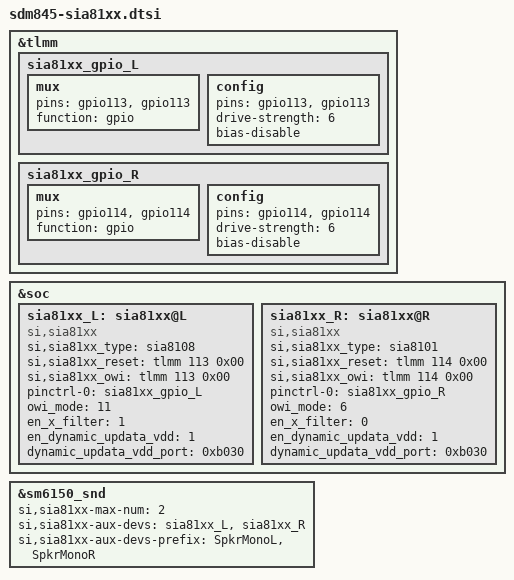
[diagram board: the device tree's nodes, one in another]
/* Copyright (c) 2018, The Linux Foundation. All rights reserved.
 *
 * This program is free software; you can redistribute it and/or modify
 * it under the terms of the GNU General Public License version 2 and
 * only version 2 as published by the Free Software Foundation.
 *
 * This program is distributed in the hope that it will be useful,
 * but WITHOUT ANY WARRANTY; without even the implied warranty of
 * MERCHANTABILITY or FITNESS FOR A PARTICULAR PURPOSE.  See the
 * GNU General Public License for more details.
 */

&tlmm {
	sia81xx_gpio_L: sia81xx_gpio_L {
		mux {
			pins = "gpio113", "gpio113";
			function = "gpio";
		};

		config {
			pins = "gpio113", "gpio113";
			drive-strength = <6>;
			bias-disable;
		};
	};

	sia81xx_gpio_R: sia81xx_gpio_R {
		mux {
			pins = "gpio114", "gpio114";
			function = "gpio";
		};

		config {
			pins = "gpio114", "gpio114";
			drive-strength = <6>;
			bias-disable;
		};
	};

};

&soc {
	sia81xx_L: sia81xx@L {
			compatible = "si,sia81xx";
			si,sia81xx_type = "sia8108";
			si,sia81xx_reset = <&tlmm 113 0x00>;
			si,sia81xx_owi = <&tlmm 113 0x00>;
			pinctrl-names = "sia81xx_gpio";
			pinctrl-0 = <&sia81xx_gpio_L>;

			owi_mode = <11>;
			en_x_filter = <1>;
			en_dynamic_updata_vdd = <1>;
			dynamic_updata_vdd_port = <0xb030>;
	};

	sia81xx_R: sia81xx@R {
			compatible = "si,sia81xx";
			si,sia81xx_type = "sia8101";
			si,sia81xx_reset = <&tlmm 114 0x00>;
			si,sia81xx_owi = <&tlmm 114 0x00>;
			pinctrl-names = "sia81xx_gpio";
			pinctrl-0 = <&sia81xx_gpio_R>;

			owi_mode = <6>;
			en_x_filter = <0>;
			en_dynamic_updata_vdd = <1>;
			dynamic_updata_vdd_port = <0xb030>;
	};

};

&sm6150_snd {
	si,sia81xx-max-num = <2>;
	si,sia81xx-aux-devs = <&sia81xx_L> , <&sia81xx_R>;
	si,sia81xx-aux-devs-prefix = "SpkrMonoL","SpkrMonoR";
};

/*
&qupv3_se11_i2c {
	status = "ok";

	sia81xx_i2c_L: sia81xx_i2c@L {
		compatible = "si,sia81xx-i2c";
		reg = <0x28>;
		si,sia81xx-dev = <&sia81xx_L>;
	};

	sia81xx_i2c_R: sia81xx_i2c@R {
		compatible = "si,sia81xx-i2c";
		reg = <0x2b>;
		si,sia81xx-dev = <&sia81xx_R>;
	};
};
*/
/*
&i2c_6 {
	sia8108_i2c_28: sia8108_i2c@28 {
		compatible = "si,sia8108-i2c";
		reg = <0x28>;
		si,sia8108-dev = <&sia8108_28>;
	};

	sia8108_i2c_2b: sia8108_i2c@2b {
		compatible = "si,sia8108-i2c";
		reg = <0x2b>;
		si,sia8108-dev = <&sia8108_2b>;
	};
};
*/
























/*
&soc {
	sia8108_28: sia8108@28 {
			compatible = "si,sia8108";
			si,sia8108-dev-name = "sia8108-28";
			si,sia8108_reset = <&tlmm 25 0x00>;
			si,sia8108_owi = <&tlmm 25 0x00>;
			pinctrl-names = "sia8108_gpio";
			pinctrl-0 = <&sia8108_gpio_L>;
	};

	sia8108_2b: sia8108@2b {
			compatible = "si,sia8108";
			si,sia8108-dev-name = "sia8108-2b";
			si,sia8108_reset = <&tlmm 26 0x00>;
			si,sia8108_owi = <&tlmm 26 0x00>;
			pinctrl-names = "sia8108_gpio";
			pinctrl-0 = <&sia8108_gpio_R>;
	};
};

&i2c_6 {
	sia8108_i2c_28: sia8108_i2c@28 {
		compatible = "si,sia8108-i2c";
		reg = <0x28>;
		si,sia8108-dev = <&sia8108_28>;
		si,sia8108-dev-name = "sia8108-28";
	};

	sia8108_i2c_2b: sia8108_i2c@2b {
		compatible = "si,sia8108-i2c";
		reg = <0x2b>;
		si,sia8108-dev = <&sia8108_2b>;
		si,sia8108-dev-name = "sia8108-2b";
	};
};
*/

/*
interrupt-parent = <&tlmm>;
interrupts = <26 0x2008>;
si-in,irq-pin = <&tlmm 26 0x2008>;
*/


